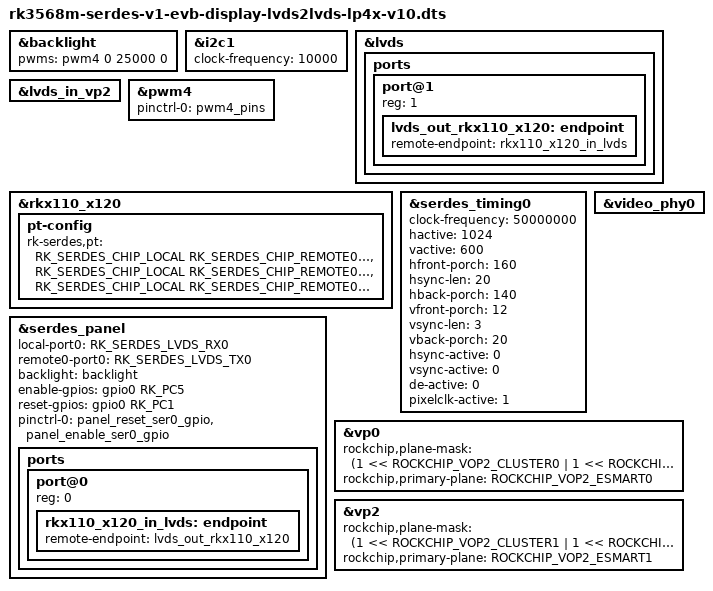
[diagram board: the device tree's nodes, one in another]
// SPDX-License-Identifier: (GPL-2.0+ OR MIT)
/*
 * Copyright (c) 2022 Rockchip Electronics Co., Ltd.
 *
 */

#include <dt-bindings/display/rockchip_vop.h>
#include "rk3568m-serdes-v1-evb-lp4x-v10.dtsi"
#include "rk3568-android.dtsi"

&backlight {
	pwms = <&pwm4 0 25000 0>;
	status = "okay";
};

&i2c1 {
	status = "okay";
	clock-frequency = <10000>;
};

&lvds {
	status = "okay";

	ports {
		#address-cells = <1>;
		#size-cells = <0>;

		port@1 {
			reg = <1>;
			lvds_out_rkx110_x120: endpoint {
				remote-endpoint = <&rkx110_x120_in_lvds>;
			};
		};
	};
};

&lvds_in_vp2 {
	status = "okay";
};

&pwm4 {
	pinctrl-names = "active";
	pinctrl-0 = <&pwm4_pins>;
	status = "okay";
};

&rkx110_x120 {
	pt-config {
		rk-serdes,pt = <RK_SERDES_CHIP_LOCAL RK_SERDES_CHIP_REMOTE0
				RK_SERDES_PASSTHROUGH_GPI_GPO_1>,
			       <RK_SERDES_CHIP_LOCAL RK_SERDES_CHIP_REMOTE0
				RK_SERDES_PASSTHROUGH_GPI_GPO_3>,
			       <RK_SERDES_CHIP_LOCAL RK_SERDES_CHIP_REMOTE0
				RK_SERDES_PASSTHROUGH_GPI_GPO_5>;
	};
};

&serdes_timing0 {
	clock-frequency = <50000000>;
	hactive = <1024>;
	vactive = <600>;
	hfront-porch = <160>;
	hsync-len = <20>;
	hback-porch = <140>;
	vfront-porch = <12>;
	vsync-len = <3>;
	vback-porch = <20>;
	hsync-active = <0>;
	vsync-active = <0>;
	de-active = <0>;
	pixelclk-active = <1>;
};

&serdes_panel {
	local-port0 = <RK_SERDES_LVDS_RX0>;
	remote0-port0 = <RK_SERDES_LVDS_TX0>;

	backlight = <&backlight>;
	enable-gpios = <&gpio0 RK_PC5 GPIO_ACTIVE_HIGH>;
	reset-gpios = <&gpio0 RK_PC1 GPIO_ACTIVE_HIGH>;
	pinctrl-names = "default";
	pinctrl-0 = <&panel_reset_ser0_gpio &panel_enable_ser0_gpio>;

	ports {
		#address-cells = <1>;
		#size-cells = <0>;

		port@0 {
			reg = <0>;
			rkx110_x120_in_lvds: endpoint {
				remote-endpoint = <&lvds_out_rkx110_x120>;
			};
		};
	};
};

&video_phy0 {
	status = "okay";
};

/* vp0 for HDMI, vp2 for rgb */
&vp0 {
	rockchip,plane-mask = <(1 << ROCKCHIP_VOP2_CLUSTER0 | 1 << ROCKCHIP_VOP2_ESMART0 |
				1 << ROCKCHIP_VOP2_SMART0)>;
	rockchip,primary-plane = <ROCKCHIP_VOP2_ESMART0>;
};

&vp2 {
	rockchip,plane-mask = <(1 << ROCKCHIP_VOP2_CLUSTER1 | 1 << ROCKCHIP_VOP2_ESMART1 |
				1 << ROCKCHIP_VOP2_SMART1)>;
	rockchip,primary-plane = <ROCKCHIP_VOP2_ESMART1>;
};
